# MEC1322 register map
Vendor: Microchip Technology Inc.; Series: ARMCM4F; File version: 1.0
CPU: CM4 r1p0, little endian, MPU, FPU, 3 interrupt priority bits
Registers are 32-bit, read-write, reset 0x0 unless marked. A register's access mark holds for its fields unless they carry their own. Offsets are from the block's base; [hi:lo] are bit positions; lines under a group give offsets from that group; {n}, {i} and the like mark numbered series; 'fields as' and 'values as' point back to an identical list.

## LPC — The registers defined for the LPC Interface block are accessible by the various hosts as indicated in Section 5.9, "LPC Configuration Registers", Section 5.10, "EC-Only Registers"and Section 5.11, "Runtime Registers".
Base 0x400F3000
0x00 INDEX 8-bit — The INDEX register, which is part of the Configuration Port, is used as a pointer to a Configuration Register Address.
0x01 DATA 8-bit — The DATA register, which is part of the Configuration Port, is used to read or write data to the register currently being selected by the INDEX Register.
0x104 BUS_MONITOR read — LPC BUS MONITOR REGISTER
  [1] LRESET_STATUS — This bit reflects the state of the LRESET# input pin. The LRESET_Status is the inverse of the LRESET# pin.
    0=Inactive (When the LRESET_Status bit is '0b', the LRESET# input pin is deasserted (that is, the pin has the value '1b').); 1=Active (When the LRESET_Status bit is '1b', the LRESET# input pin is asserted (that is, the pin has the value '0b').)
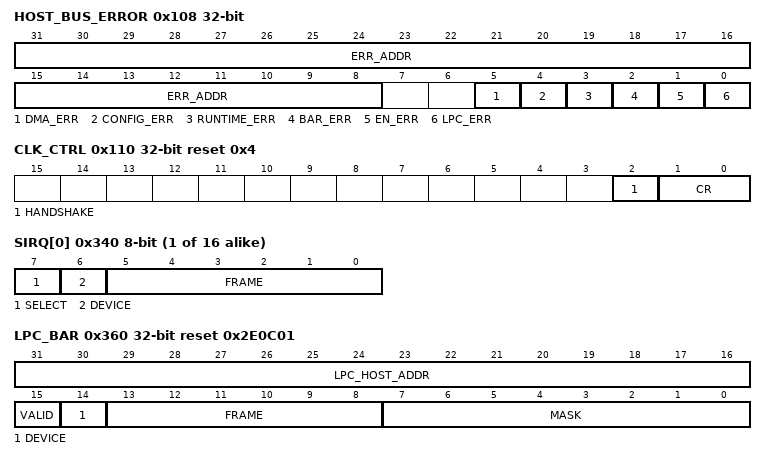
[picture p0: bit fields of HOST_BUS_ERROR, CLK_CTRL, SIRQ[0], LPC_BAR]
0x108 HOST_BUS_ERROR (reset mask 0xFFFF)
  [31:8] ERR_ADDR ro — This 24-bit field captures the 24-bit internal address of every LPC transaction whenever the bit LPC_INTERNAL_ERR in this register is 0.
  [5] DMA_ERR — EN_INTERNAL_ERR is 1 and an LPC DMA access causes an internal bus error. (R/WC)
  [4] CONFIG_ERR — EN_INTERNAL_ERR is 1 and an LPC Configuration access causes an internal bus error. (R/WC)
  [3] RUNTIME_ERR — EN_INTERNAL_ERR is 1 and an LPC I/O access causes an internal bus error. This error will only occur if a BAR is misconfigured. (R/WC)
  [2] BAR_ERR — a BAR conflict occurs on an LPC address. (R/WC)
  [1] EN_ERR — Internal bus errors will also cause LPC_INTERNAL_ERR to be set. (R/WC)
  [0] LPC_ERR — A BAR conflict or an internal bus error occurs as a result of an LPC access. (R/WC)
0x10C EC_SERIRQ — If the LPC Logical Device is selected as the source for a Serial Interrupt Request by an Interrupt Configuration register, this bit is used as the interrupt source.
  [0] EC_IRQ — This bit is used as the interrupt source of a LPC Logical Device
0x110 CLK_CTRL reset 0x4 — Controls throughput of LPC transactions.
  [2] HANDSHAKE — This bit controls throughput of LPC transactions.
  [1:0] CR — This field controls when the host interface will permit the internal ring oscillator to be shut down.
0x120 BAR_INHIBIT (reset mask 0xFFFF) — The BAR for Logical Device i is disabled and its addresses will not be claimed on the LPC bus
0x130 BAR_INIT reset 0x2E (reset mask 0xFF) — This field is loaded into the LPC BAR at offset 60h on nSIO_RESET.
0x330 ACTIVATE 8-bit — The LPC Logical Device is powered and functional.
{0x340+i} SIRQ[{i}] (i=0..15) 8-bit — The LPC Controller implements 16 IRQ channels that may be configured to be asserted by any logical device.
  [7] SELECT — If this bit is 1, the first interrupt signal from the Logical Device is selected for the SERIRQ vector. If this bit is 0, the second interrupt signal from the Logical Device is selected.
  [6] DEVICE — This field should always be set to 0 in order to enable a SERIRQ.
  [5:0] FRAME — These six bits select the Logical Device for on-chip devices as the source for the interrupt.
0x360 LPC_BAR reset 0x2E0C01 — LPC Interface BAR Register
  [31:16] LPC_HOST_ADDR — These 16 bits are used to match LPC I/O addresses
  [15] VALID — If this bit is 1, the BAR is valid and will participate in LPC matches. If it is 0 this BAR is ignored
  [14] DEVICE — This bit combined with FRAME constitute the Logical Device Number. DEVICE identifies the physical location of the logical device.
  [13:8] FRAME — These 6 bits are used to specify a logical device frame number within a bus.
  [7:0] MASK — These 8 bits are used to mask off address bits in the address match between an LPC I/O address and the Host Address field of the BARs
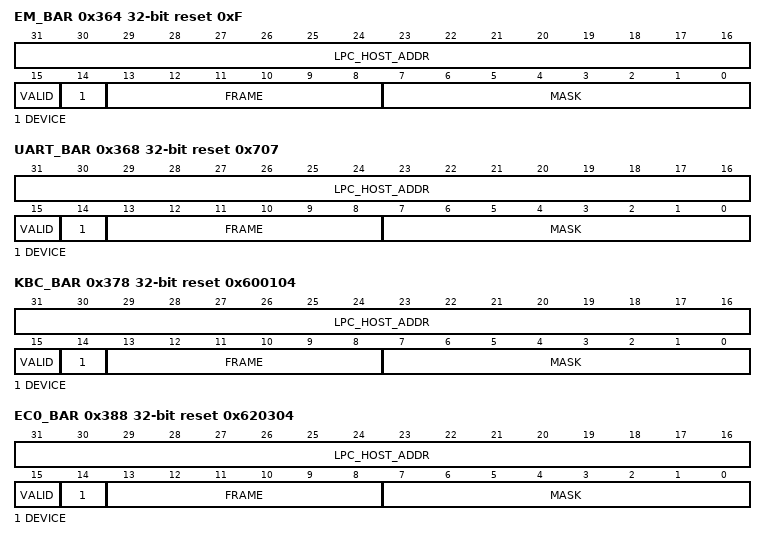
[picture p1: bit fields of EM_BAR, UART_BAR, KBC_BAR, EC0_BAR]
0x364 EM_BAR reset 0xF — EM Interface 0 BAR
  fields as LPC_BAR
0x368 UART_BAR reset 0x707 — UART 0 BAR Register
  fields as LPC_BAR
0x378 KBC_BAR reset 0x600104 — Keyboard Controller (8042) BAR
  fields as LPC_BAR
0x388 EC0_BAR reset 0x620304 — ACPI EC Interface 0 BAR
  fields as LPC_BAR
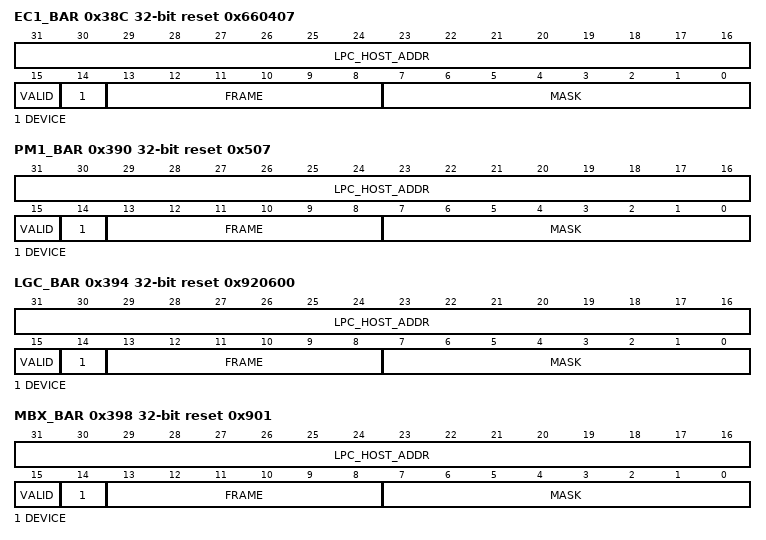
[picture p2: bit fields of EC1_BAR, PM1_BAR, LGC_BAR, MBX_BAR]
0x38C EC1_BAR reset 0x660407 — ACPI EC Interface 1 BAR
  fields as LPC_BAR
0x390 PM1_BAR reset 0x507 — ACPI PM1 Interface BAR
  fields as LPC_BAR
0x394 LGC_BAR reset 0x920600 — Legacy (GATEA20) Interface BAR
  fields as LPC_BAR
0x398 MBX_BAR reset 0x901 — Mailbox Registers Interface BAR
  fields as LPC_BAR
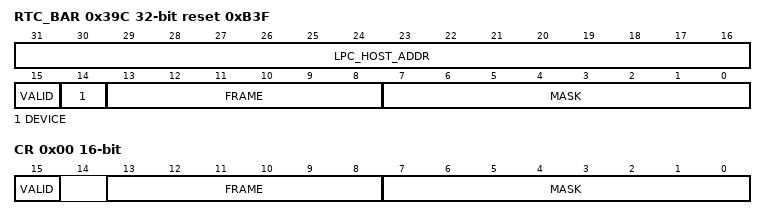
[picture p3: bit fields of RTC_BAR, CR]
0x39C RTC_BAR reset 0xB3F — RTC Registers Interface BAR
  fields as LPC_BAR
0x3C0 MBX_MEM_BAR group — Mailbox Registers I/F Memory BAR
  0x00 CR 16-bit — MEM_BAR Control [15:0]
    [15] VALID — If this bit is 1, the BAR is valid and will participate in LPC matches. If it is 0 this BAR is ignored.
    [13:8] FRAME — These 6 bits are used to specify a logical device frame number within a bus. This field is multiplied by 400h to provide the frame address within the peripheral bus address
    [7:0] MASK — These bits are used to mask off address bits in the address match between an LPC memory address and the Host Address field of the BARs
  0x02 HOST_LO_ADDR 16-bit — HOST_ADDRESS[15:0] These 16 bits are used to match LPC memory addresses.
  0x04 HOST_HI_ADDR 16-bit — HOST_ADDRESS[31:16] These 16 bits are used to match LPC memory addresses.
0x3C6 EC0_MEM_BAR group — ACPI EC Interface 0 Memory BAR
  0x00 CR 16-bit — MEM_BAR Control [15:0]
    fields as MBX_MEM_BAR.CR
  0x02 HOST_LO_ADDR 16-bit — HOST_ADDRESS[15:0] These 16 bits are used to match LPC memory addresses.
  0x04 HOST_HI_ADDR 16-bit — HOST_ADDRESS[31:16] These 16 bits are used to match LPC memory addresses.
0x3CC EC1_MEM_BAR group — ACPI EC Interface 1 Memory BAR
  0x00 CR 16-bit — MEM_BAR Control [15:0]
    fields as MBX_MEM_BAR.CR
  0x02 HOST_LO_ADDR 16-bit — HOST_ADDRESS[15:0] These 16 bits are used to match LPC memory addresses.
  0x04 HOST_HI_ADDR 16-bit — HOST_ADDRESS[31:16] These 16 bits are used to match LPC memory addresses.
0x3D2 EMI_MEM_BAR group — EM Interface 0 Memory BAR
  0x00 CR 16-bit — MEM_BAR Control [15:0]
    fields as MBX_MEM_BAR.CR
  0x02 HOST_LO_ADDR 16-bit — HOST_ADDRESS[15:0] These 16 bits are used to match LPC memory addresses.
  0x04 HOST_HI_ADDR 16-bit — HOST_ADDRESS[31:16] These 16 bits are used to match LPC memory addresses.
